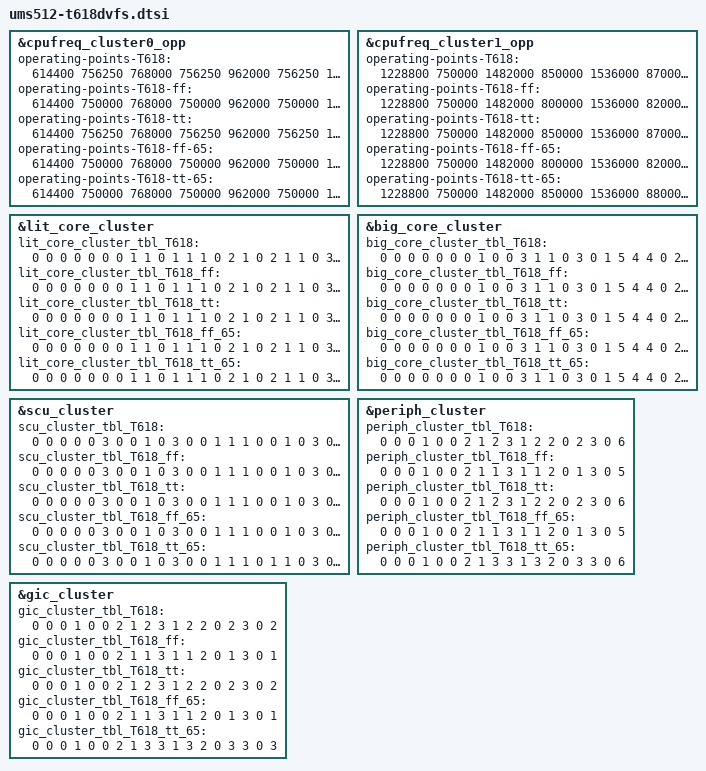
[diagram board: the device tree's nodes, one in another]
// SPDX-License-Identifier: (GPL-2.0+ OR MIT)
/*
 * Unisoc Sharkl5Pro platform T618 SOC DVFS DTS file
 *
 * Copyright (C) 2019, Unisoc Communications Inc.
 */

#include "sharkl5Pro.dtsi"
#include "ums512.dtsi"

&cpufreq_cluster0_opp {
	/* operating-points-T618-0-0
	 * T618/T618-soc_ver 0-binning 0-temp
	 * T618-T618 v1-T610
	 */
	operating-points-T618 = <
		/* kHZ   uV */
		614400  756250
		768000  756250
		962000  756250
		1144000 756250
		1228800 787500
		1482000 875000
		1536000 890625
		1716000 953125
		1820000 990625
		2002000 1050000
	>;

	operating-points-T618-ff = <
		/* kHZ   uV */
		614400  750000
		768000  750000
		962000  750000
		1144000 750000
		1228800 750000
		1482000 825000
		1536000 840625
		1716000 903125
		1820000 940625
		2002000 1000000
	>;

	operating-points-T618-tt = <
		/* kHZ   uV */
		614400  756250
		768000  756250
		962000  756250
		1144000 756250
		1228800 787500
		1482000 875000
		1536000 890625
		1716000 953125
		1820000 990625
		2002000 1050000
	>;

	operating-points-T618-ff-65 = <
		/* kHZ   uV */
		614400  750000
		768000  750000
		962000  750000
		1144000 750000
		1228800 750000
		1482000 834375
		1536000 853125
		1716000 921875
		1820000 959375
		2002000 1021875
	>;

	operating-points-T618-tt-65 = <
		/* kHZ   uV */
		614400  750000
		768000  750000
		962000  750000
		1144000 762500
		1228800 793750
		1482000 884375
		1536000 906250
		1716000 971875
		1820000 1009375
	>;
};

&cpufreq_cluster1_opp {
	operating-points-T618 = <
		/* kHZ   uV */
		1228800	750000
		1482000	850000
		1536000	870000
		1742000 950000
		1872000 1000000
		2002000 1050000
	>;

	operating-points-T618-ff = <
		/* kHZ   uV */
		1228800	750000
		1482000	800000
		1536000	820000
		1742000 900000
		1872000 950000
		2002000 1000000
	>;

	operating-points-T618-tt = <
		/* kHZ   uV */
		1228800	750000
		1482000	850000
		1536000	870000
		1742000 950000
		1872000 1000000
		2002000 1050000
	>;

	operating-points-T618-ff-65 = <
		/* kHZ   uV */
		1228800	750000
		1482000	800000
		1536000	820000
		1742000 910000
		1872000 970000
		2002000 1020000
	>;

	operating-points-T618-tt-65 = <
		/* kHZ   uV */
		1228800	750000
		1482000	850000
		1536000	880000
		1742000 960000
		1872000 1020000
	>;
};

&lit_core_cluster{
	/* lit_core_cluster_tbl_T618_0_0
	 * T618/v1-soc_ver T618-T618 v1-T610 0-binning 0-temp
	 * sel, div, vol, vote_scu, vote_peri, vote_gic, mpllx
	 */
	lit_core_cluster_tbl_T618 = <
		0 0 0 0 0 0 0
		1 1 0 1 1 1 0
		2 1 0 2 1 1 0
		3 0 0 2 1 1 0
		3 0 0 3 1 1 1
		1 0 1 4 1 1 0
		3 0 2 5 4 4 2
		2 0 3 6 4 4 0
		3 0 4 7 4 5 3
		3 0 5 8 4 5 4
		3 0 6 9 5 5 5
	>;

	lit_core_cluster_tbl_T618_ff = <
		0 0 0 0 0 0 0
		1 1 0 1 1 1 0
		2 1 0 2 1 1 0
		3 0 0 2 1 1 0
		3 0 0 3 1 1 1
		1 0 0 4 1 1 0
		3 0 1 5 4 4 2
		2 0 2 6 4 4 0
		3 0 3 7 4 5 3
		3 0 4 8 4 5 4
		3 0 5 9 5 5 5
	>;

	lit_core_cluster_tbl_T618_tt = <
		0 0 0 0 0 0 0
		1 1 0 1 1 1 0
		2 1 0 2 1 1 0
		3 0 0 2 1 1 0
		3 0 0 3 1 1 1
		1 0 1 4 1 1 0
		3 0 2 5 4 4 2
		2 0 3 6 4 4 0
		3 0 4 7 4 5 3
		3 0 5 8 4 5 4
		3 0 6 9 5 5 5
	>;

	lit_core_cluster_tbl_T618_ff_65 = <
		0 0 0 0 0 0 0
		1 1 0 1 1 1 0
		2 1 0 2 1 1 0
		3 0 0 2 1 1 0
		3 0 0 3 1 1 1
		1 0 0 4 1 1 0
		3 0 1 5 4 4 2
		2 0 2 6 4 4 0
		3 0 3 7 4 5 3
		3 0 4 8 4 5 4
		3 0 5 9 5 5 5
	>;

	lit_core_cluster_tbl_T618_tt_65 = <
		0 0 0 0 0 0 0
		1 1 0 1 1 1 0
		2 1 0 2 1 1 0
		3 0 0 2 1 1 0
		3 0 1 3 1 1 1
		1 0 2 4 1 1 0
		3 0 3 5 4 4 2
		2 0 4 6 4 4 0
		3 0 5 7 4 5 3
		3 0 6 8 4 5 4
		3 0 6 8 4 5 4
	>;
};

&big_core_cluster {
	/* sel, div, vol, vote_scu, vote_peri, vote_gic, mpllx */
	big_core_cluster_tbl_T618 = <
		0 0 0 0 0 0 0
		1 0 0 3 1 1 0
		3 0 1 5 4 4 0
		2 0 2 6 4 4 0
		3 0 3 7 4 5 1
		3 0 4 8 4 5 3
		3 0 5 9 5 5 4
	>;

	big_core_cluster_tbl_T618_ff = <
		0 0 0 0 0 0 0
		1 0 0 3 1 1 0
		3 0 1 5 4 4 0
		2 0 2 6 4 4 0
		3 0 3 7 4 5 1
		3 0 4 8 4 5 3
		3 0 5 9 5 5 4
	>;

	big_core_cluster_tbl_T618_tt = <
		0 0 0 0 0 0 0
		1 0 0 3 1 1 0
		3 0 1 5 4 4 0
		2 0 2 6 4 4 0
		3 0 3 7 4 5 1
		3 0 4 8 4 5 3
		3 0 5 9 5 5 4
	>;

	big_core_cluster_tbl_T618_ff_65 = <
		0 0 0 0 0 0 0
		1 0 0 3 1 1 0
		3 0 1 5 4 4 0
		2 0 2 6 4 4 0
		3 0 3 7 4 5 1
		3 0 4 8 4 5 3
		3 0 5 9 5 5 4
	>;

	big_core_cluster_tbl_T618_tt_65 = <
		0 0 0 0 0 0 0
		1 0 0 3 1 1 0
		3 0 1 5 4 4 0
		2 0 2 6 4 4 0
		3 0 3 7 4 5 1
		3 0 4 8 4 5 3
		3 0 4 8 4 5 3
	>;
};

&scu_cluster {
	/* sel div vol ace_div mpllx */
	scu_cluster_tbl_T618 = <
		0 0 0 0 0
		3 0 0 1 0
		3 0 0 1 1
		1 0 0 1 0
		3 0 1 1 2
		3 0 2 1 3
		3 0 3 1 4
		3 0 4 1 5
		3 0 5 1 6
		3 0 6 1 7
	>;

	scu_cluster_tbl_T618_ff = <
		0 0 0 0 0
		3 0 0 1 0
		3 0 0 1 1
		1 0 0 1 0
		3 0 0 1 2
		3 0 1 1 3
		3 0 2 1 4
		3 0 3 1 5
		3 0 4 1 6
		3 0 5 1 7
	>;

	scu_cluster_tbl_T618_tt = <
		0 0 0 0 0
		3 0 0 1 0
		3 0 0 1 1
		1 0 0 1 0
		3 0 1 1 2
		3 0 2 1 3
		3 0 3 1 4
		3 0 4 1 5
		3 0 5 1 6
		3 0 6 1 7
	>;

	scu_cluster_tbl_T618_ff_65 = <
		0 0 0 0 0
		3 0 0 1 0
		3 0 0 1 1
		1 0 0 1 0
		3 0 0 1 2
		3 0 1 1 3
		3 0 2 1 4
		3 0 3 1 5
		3 0 4 1 6
		3 0 5 1 7
	>;

	scu_cluster_tbl_T618_tt_65 = <
		0 0 0 0 0
		3 0 0 1 0
		3 0 0 1 1
		1 0 1 1 0
		3 0 2 1 2
		3 0 3 1 3
		3 0 4 1 4
		3 0 5 1 5
		3 0 6 1 6
		3 0 6 1 6
	>;
};

&periph_cluster{
	/* sel div vol */
	periph_cluster_tbl_T618 = <
		0 0 0
		1 0 0
		2 1 2
		3 1 2
		2 0 2
		3 0 6
	>;

	periph_cluster_tbl_T618_ff = <
		0 0 0
		1 0 0
		2 1 1
		3 1 1
		2 0 1
		3 0 5
	>;

	periph_cluster_tbl_T618_tt = <
		0 0 0
		1 0 0
		2 1 2
		3 1 2
		2 0 2
		3 0 6
	>;

	periph_cluster_tbl_T618_ff_65 = <
		0 0 0
		1 0 0
		2 1 1
		3 1 1
		2 0 1
		3 0 5
	>;

	periph_cluster_tbl_T618_tt_65 = <
		0 0 0
		1 0 0
		2 1 3
		3 1 3
		2 0 3
		3 0 6
	>;
};

&gic_cluster {
	/*sel div vol*/
	gic_cluster_tbl_T618 = <
		0 0 0
		1 0 0
		2 1 2
		3 1 2
		2 0 2
		3 0 2
	>;

	gic_cluster_tbl_T618_ff = <
		0 0 0
		1 0 0
		2 1 1
		3 1 1
		2 0 1
		3 0 1
	>;

	gic_cluster_tbl_T618_tt = <
		0 0 0
		1 0 0
		2 1 2
		3 1 2
		2 0 2
		3 0 2
	>;

	gic_cluster_tbl_T618_ff_65 = <
		0 0 0
		1 0 0
		2 1 1
		3 1 1
		2 0 1
		3 0 1
	>;

	gic_cluster_tbl_T618_tt_65 = <
		0 0 0
		1 0 0
		2 1 3
		3 1 3
		2 0 3
		3 0 3
	>;
};
